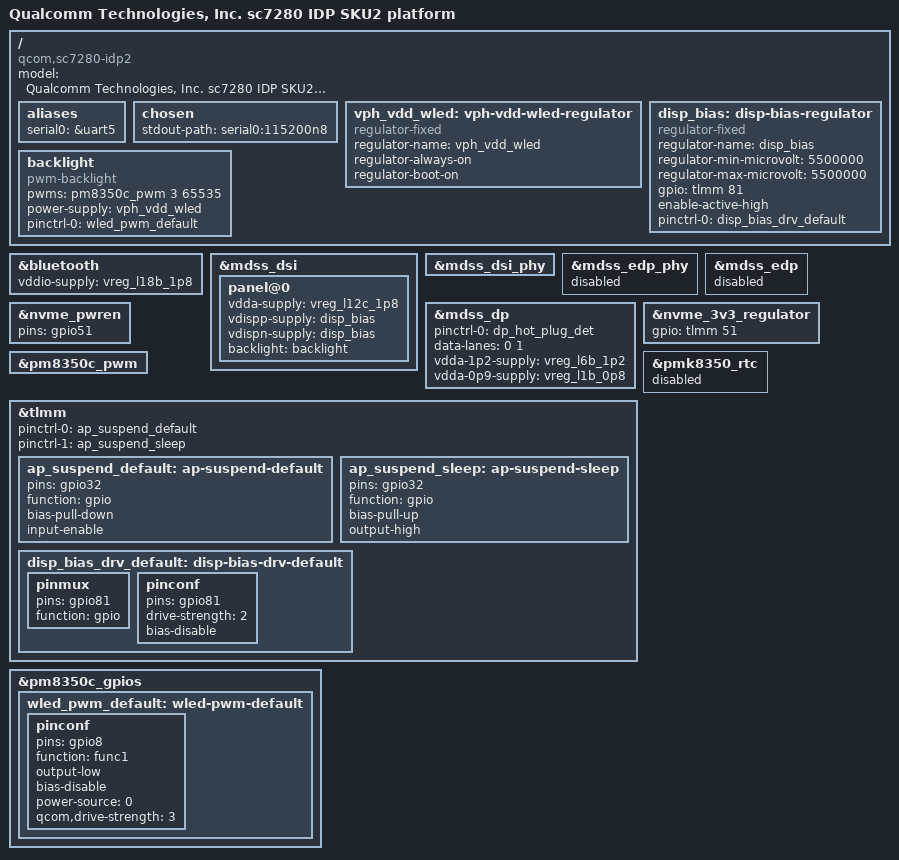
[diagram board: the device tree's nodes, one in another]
// SPDX-License-Identifier: BSD-3-Clause
/*
 * sc7280 IDP2 board device tree source
 *
 * Copyright (c) 2021, The Linux Foundation. All rights reserved.
 */

/dts-v1/;

#include "sc7280-idp.dtsi"
#include "sc7280-idp-ec-h1.dtsi"

/ {
	model = "Qualcomm Technologies, Inc. sc7280 IDP SKU2 platform";
	compatible = "qcom,sc7280-idp2", "google,piglin", "qcom,sc7280";

	aliases {
		serial0 = &uart5;
	};

	chosen {
		stdout-path = "serial0:115200n8";
	};
};

&bluetooth {
	vddio-supply = <&vreg_l18b_1p8>;
};

&mdss_dsi {
        panel@0 {
                vdda-supply = <&vreg_l12c_1p8>;
                vdispp-supply = <&disp_bias>;
                vdispn-supply = <&disp_bias>;

                backlight = <&backlight>;
        };
};

&mdss_dsi_phy {
        status = "okay";
};

&mdss_edp_phy {
        status = "disabled";
};

&mdss_dp {
       status = "okay";
       pinctrl-names = "default";
       pinctrl-0 = <&dp_hot_plug_det>;
       data-lanes = <0 1>;
       vdda-1p2-supply = <&vreg_l6b_1p2>;
       vdda-0p9-supply = <&vreg_l1b_0p8>;
};

&mdss_edp {
        status = "disabled";
};

&nvme_pwren {
	pins = "gpio51";
};

&nvme_3v3_regulator {
	gpio = <&tlmm 51 GPIO_ACTIVE_HIGH>;
};

&pm8350c_pwm {
	status = "okay";
};

&pmk8350_rtc {
        status = "disabled";
};

&tlmm {
	pinctrl-names = "default" , "sleep";
	pinctrl-0 = <&ap_suspend_default>;
	pinctrl-1 = <&ap_suspend_sleep>;

	ap_suspend_default: ap-suspend-default {
		pins = "gpio32";
		function = "gpio";
		bias-pull-down;
		input-enable;
	};

	ap_suspend_sleep: ap-suspend-sleep {
		pins = "gpio32";
		function = "gpio";
		bias-pull-up;
		output-high;
	};
	
	disp_bias_drv_default: disp-bias-drv-default {
		pinmux {
			pins = "gpio81";
			function = "gpio";
		};

		pinconf {
			pins = "gpio81";
			drive-strength = <2>;
			bias-disable;
		};
	};
};

&pm8350c_gpios {
	wled_pwm_default: wled-pwm-default {
		pinconf {
			pins = "gpio8";
			function = "func1";
			output-low;
			bias-disable;
			power-source = <0>;
			qcom,drive-strength = <3>;
		};
	};
};

/ {
	vph_vdd_wled: vph-vdd-wled-regulator {
		compatible = "regulator-fixed";
		regulator-name = "vph_vdd_wled";
		regulator-always-on;
		regulator-boot-on;
	};

	disp_bias: disp-bias-regulator {
		compatible = "regulator-fixed";
		regulator-name = "disp_bias";

		regulator-min-microvolt = <5500000>;
		regulator-max-microvolt = <5500000>;

		gpio = <&tlmm 81 GPIO_ACTIVE_HIGH>;
		enable-active-high;

		pinctrl-names = "default";
		pinctrl-0 = <&disp_bias_drv_default>;
	};

	backlight: backlight {
		compatible = "pwm-backlight";

		pwms = <&pm8350c_pwm 3 65535>;
		power-supply = <&vph_vdd_wled>;

		pinctrl-names = "default";
		pinctrl-0 = <&wled_pwm_default>;
	};
};

